AUTOSAR XML (schema 4-2-1)
package /ComponentTypes
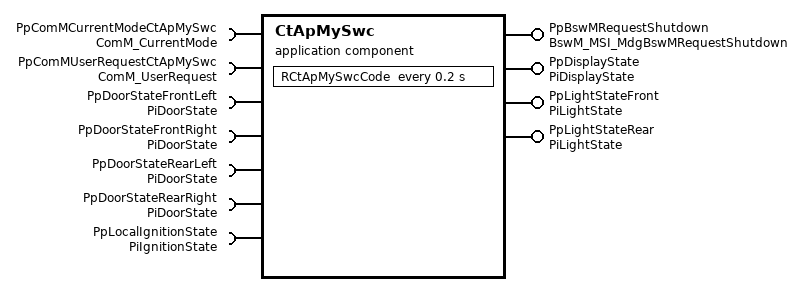
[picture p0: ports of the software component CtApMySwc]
  application sw component type CtApMySwc
    4 x provide port:
      PpBswMRequestShutdown: mode-switch-sender-com-spec{enhanced-mode-api=false, mode-group=BswM_MDGP_MdgBswMRequestShutdown, queue-length=1}, provided-interface=BswM_MSI_MdgBswMRequestShutdown
      PpDisplayState: provided-interface=PiDisplayState
        provided-com-specs:
          data-element=DeDisplayBusState, init-value=constant-reference=CDisplayOff
          data-element=DeLightOnOffCounter, init-value=constant-reference=CUInt32Zero
          data-element=DeOdometerValue, init-value=constant-reference=CUInt32Zero
          data-element=DeOdometerWriteRequestPending, init-value=constant-reference=CWriteReqNotPending
      PpLightStateFront: nonqueued-sender-com-spec{data-element=DeLightState, init-value=constant-reference=CLightOff}, provided-interface=PiLightState
      PpLightStateRear: nonqueued-sender-com-spec{data-element=DeLightState, init-value=constant-reference=CLightOff}, provided-interface=PiLightState
    7 x require port:
      PpComMCurrentModeCtApMySwc: mode-switch-receiver-com-spec{enhanced-mode-api=false, supports-asynchronous-mode-switch=false}, required-interface=ComM_CurrentMode
      PpComMUserRequestCtApMySwc: required-interface=ComM_UserRequest
      PpDoorStateFrontLeft: nonqueued-receiver-com-spec{data-element=DeDoorState, filter=data-filter-type=ALWAYS, init-value=constant-reference=CDoorClosed}, required-interface=PiDoorState
      PpDoorStateFrontRight: nonqueued-receiver-com-spec{data-element=DeDoorState, filter=data-filter-type=ALWAYS, init-value=constant-reference=CDoorClosed}, required-interface=PiDoorState
      PpDoorStateRearLeft: nonqueued-receiver-com-spec{data-element=DeDoorState, filter=data-filter-type=ALWAYS, init-value=constant-reference=CDoorClosed}, required-interface=PiDoorState
      PpDoorStateRearRight: nonqueued-receiver-com-spec{data-element=DeDoorState, filter=data-filter-type=ALWAYS, init-value=constant-reference=CDoorClosed}, required-interface=PiDoorState
      PpLocalIgnitionState: nonqueued-receiver-com-spec{data-element=DeIgnitionState, filter=data-filter-type=ALWAYS, init-value=0}, required-interface=PiIgnitionState
    behavior CtApMySwc_InternalBehavior: data-type-mapping=DemoTypeMapping
      init event CtApMySwc_InitEvent: start-on-event=RCtApMySwc_Init
      timing event TMT_RCtApMySwcCode: start-on-event=RCtApMySwcCode, period=0.2
      swc mode switch event MST_RCtApMySwcComM_ModeChange_FULL_COMM_Entry_0: start-on-event=RCtApMySwcComM_ModeChange_FULL_COMM_Entry, activation=ON-ENTRY, mode=PpComMCurrentModeCtApMySwc.currentMode.COMM_FULL_COMMUNICATION
      swc mode switch event MST_RCtApMySwcComM_ModeChange_FULL_COMM_Exit_0: start-on-event=RCtApMySwcComM_ModeChange_FULL_COMM_Exit, activation=ON-EXIT, mode=PpComMCurrentModeCtApMySwc.currentMode.COMM_FULL_COMMUNICATION
      4 x runnable:
        RCtApMySwc_Init
          data-send-points:
            access SEND_PpDisplayState_DeLightOnOffCounter: accessed-variable=PpDisplayState.DeLightOnOffCounter
        RCtApMySwcCode: mode-access-point=PpBswMRequestShutdown.BswM_MDGP_MdgBswMRequestShutdown
          data-read-access:
            access REC_PpDoorStateFrontLeft_Element: accessed-variable=PpDoorStateFrontLeft.DeDoorState
            access REC_PpDoorStateRearLeft_DeDoorState: accessed-variable=PpDoorStateRearLeft.DeDoorState
          data-receive-point-by-arguments:
            access REC_PpDoorStateFrontRight_Element: accessed-variable=PpDoorStateFrontRight.DeDoorState
            access REC_PpDoorStateRearRight_DeDoorState: accessed-variable=PpDoorStateRearRight.DeDoorState
            access REC_PpLocalIgnitionState_DeIgnitionState: accessed-variable=PpLocalIgnitionState.DeIgnitionState
          data-send-points:
            6 x access:
              SEND_PpDisplayState_DeDisplayBusState: accessed-variable=PpDisplayState.DeDisplayBusState
              SEND_PpDisplayState_DeLightOnOffCounter: accessed-variable=PpDisplayState.DeLightOnOffCounter
              SEND_PpDisplayState_DeOdometerValue: accessed-variable=PpDisplayState.DeOdometerValue
              SEND_PpDisplayState_DeOdometerWriteRequrestPending: accessed-variable=PpDisplayState.DeOdometerWriteRequestPending
              SEND_PpLightStateFront_Element: accessed-variable=PpLightStateFront.DeLightState
              SEND_PpLightStateRear_DeLightState: accessed-variable=PpLightStateRear.DeLightState
          mode switch point SWITCH_PpBswMRequestShutdown_BswM_MDGP_MdgBswMRequestShutdown: mode-group=PpBswMRequestShutdown.BswM_MDGP_MdgBswMRequestShutdown
          sync call SC_PpComMUserRequestCtApMySwc_RequestComMode: operation=PpComMUserRequestCtApMySwc.RequestComMode, timeout=0
        RCtApMySwcComM_ModeChange_FULL_COMM_Entry
          data-send-points:
            access SEND_PpDisplayState_DeDisplayBusState: accessed-variable=PpDisplayState.DeDisplayBusState
        RCtApMySwcComM_ModeChange_FULL_COMM_Exit
          data-send-points:
            access SEND_PpDisplayState_DeDisplayBusState: accessed-variable=PpDisplayState.DeDisplayBusState
  swc implementation CtApMySwc_Implementation: behavior=CtApMySwc_InternalBehavior
    code-descriptors:
      code Default: artifact-descriptors=autosar-engineering-object={short-label=Default, category=SWSRC}
